# H616 register map
Vendor: Allwinner; Series: H616; File version: 0.1
CPU: other 0, little endian, MPU, no FPU, 0 interrupt priority bits
Registers are 32-bit, read-write, reset 0x0 unless marked. A register's access mark holds for its fields unless they carry their own. Offsets are from the block's base; [hi:lo] are bit positions; 'fields as' and 'values as' point back to an identical list.

## TWI0
Base 0x05002000
Same registers: TWI1 0x05002400, TWI2 0x05002800, TWI3 0x05002C00, TWI4 0x05003000, R-TWI0 0x07081400
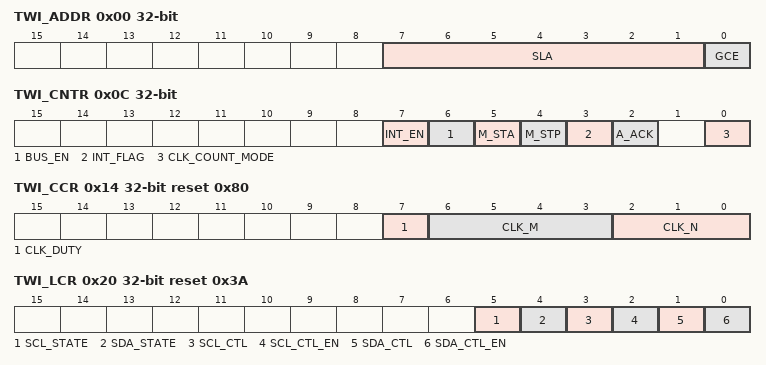
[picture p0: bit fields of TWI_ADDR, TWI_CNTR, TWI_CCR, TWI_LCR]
0x00 TWI_ADDR — TWI Slave Address
  [7:1] SLA — Slave Address 7-bit addressing: SLA6, SLA5, SLA4, SLA3, SLA2, SLA1, SLA0 10-bit addressing: 1, 1, 1, 1, 0, SLAX[9:8]
  [0] GCE — General Call Address Enable 0: Disable 1: Enable
    0=Disable; 1=Enable
0x04 TWI_XADDR — TWI Extended Slave Address
  [7:0] SLAX — Extend Slave Address SLAX[7:0]
0x08 TWI_DATA — TWI Data Byte
  [7:0] TWI_DATA — Data byte transmitted or received
0x0C TWI_CNTR — TWI Control Register
  [7] INT_EN — Interrupt Enable 0: The interrupt line always low 1: The interrupt line will go high when INT_FLAG is set.
    0=interrupt_line_always_low (The interrupt line always low); 1=interrupt_line_will_go (The interrupt line will go high when INT_FLAG is set.)
  [6] BUS_EN — TWI Bus Enable 0: The TWI bus ISDA/ISCL is ignored and the TWI Controller will not respond to any address on the bus 1: The TWI will respond to call to its slave address - and to the general call address if the GCE bit in the ADDR register is set. Note: In master operation mode, this bit should be set to `1`.
    0=TWI_bus (The TWI bus ISDA/ISCL is ignored and the TWI Controller will not respond to any address on the bus); 1=TWI_will_respond (The TWI will respond to call to its slave address - and to the general call address if the GCE bit in the ADDR register is set. Note: In master operation mode, this bit should be set to `1`.)
  [5] M_STA — Master Mode Start When M_STA is set to `1`, TWI Controller enters master mode and will transmit a START condition on the bus when the bus is free. If the M_STA bit is set to `1` when the TWI Controller is already in master mode and one or more bytes have been transmitted, then a repeated START condition will be sent. If the M_STA bit is set to `1` when the TWI is being accessed in slave mode, the TWI will complete the data transfer in slave mode then enter master mode when the bus has been released. The M_STA bit is cleared automatically after a START condition has been sent. Writing a `0` to this bit has no effect.
  [4] M_STP write-1-clears — Master Mode Stop If M_STP is set to `1` in master mode, a STOP condition is transmitted on the TWI bus. If the M_STP bit is set to `1` in slave mode, the TWI will indicate if a STOP condition has been received, but no STOP condition will be transmitted on the TWI bus. If both M_STA and M_STP bits are set, the TWI will first transmit the STOP condition (if in master mode) then transmit the START condition. The M_STP bit is cleared automatically: writing a `0` to this bit has no effect.
  [3] INT_FLAG write-1-clears — Interrupt Flag INT_FLAG is automatically set to `1` when any of 28 (out of the possible 29) states is entered (see `STAT Register` below). The only state that does not set INT_FLAG is state F8h. If the INT_EN bit is set, the interrupt line goes high when IFLG is set to `1`. If the TWI is operating in slave mode, data transfer is suspended when INT_FLAG is set and the low period of the TWI bus clock line (SCL) is stretched until `1` is written to INT_FLAG. The TWI clock line is then released and the interrupt line goes low.
  [2] A_ACK — Assert Acknowledge When A_ACK is set to `1`, an Acknowledge (low level on SDA) will be sent during the acknowledge clock pulse on the TWI bus if: (1). Either the whole of a matching 7-bit slave address or the first or the second byte of a matching 10-bit slave address has been received. (2). The general call address has been received and the GCE bit in the ADDR register is set to `1`. (3). A data byte has been received in master or slave mode. When A_ACK is `0`, a Not Acknowledge (high level on SDA) will be sent when a data byte is received in master or slave mode. If A_ACK is cleared to `0` in slave transmitter mode, the byte in the DATA register is assumed to be the `last byte`. After this byte has been transmitted, the TWI will enter state C8h then return to the idle state (status code F8h) when INT_FLAG is cleared. The TWI will not respond as a slave unless A_ACK is set.
  [0] CLK_COUNT_MODE — 0: scl clock high period count on oscl 1: scl clock high period count on iscl
    0=scl_clock_high_period_count_on_oscl; 1=scl_clock_high_period_count_on_iscl
0x10 TWI_STAT reset 0xF8 — TWI Status Register
  [7:0] STA ro — Status Information Byte Code Status 0x00: Bus error 0x08: START condition transmitted 0x10: Repeated START condition transmitted 0x18: Address + Write bit transmitted, ACK received 0x20: Address + Write bit transmitted, ACK not received 0x28: Data byte transmitted in master mode, ACK received 0x30: Data byte transmitted in master mode, ACK not received 0x38: Arbitration lost in address or data byte 0x40: Address + Read bit transmitted, ACK received 0x48: Address + Read bit transmitted, ACK not received 0x50: Data byte received in master mode, ACK transmitted 0x58: Data byte received in master mode, not ACK transmitted 0x60: Slave address + Write bit received, ACK transmitted 0x68: Arbitration lost in address as master, slave address + Write bit received, ACK transmitted 0x70: General Call address received, ACK transmitted 0x78: Arbitration lost in address as master, General Call address received, ACK transmitted 0x80: Data byte received after slave address received, ACK transmitted 0x88: Data byte received after slave address received, not ACK transmitted 0x90: Data byte received after General Call received, ACK transmitted 0x98: Data byte received after General Call received, not ACK transmitted 0xA0: STOP or repeated START condition received in slave mode 0xA8: Slave address + Read bit received, ACK transmitted 0xB0: Arbitration lost in address as master, slave address + Read bit received, ACK transmitted 0xB8: Data byte transmitted in slave mode, ACK received 0xC0: Data byte transmitted in slave mode, ACK not received 0xC8: Last byte transmitted in slave mode, ACK received 0xD0: Second Address byte + Write bit transmitted, ACK received 0xD8: Second Address byte + Write bit transmitted, ACK not received 0xF8: No relevant status information, INT_FLAG=0 Others: Reserved
0x14 TWI_CCR reset 0x80 — TWI Clock Control Register
  [7] CLK_DUTY — Setting duty cycle of Clock as Master 0: 50% 1: 40%
    0=_50_percent_; 1=_40_percent_
  [6:3] CLK_M
  [2:0] CLK_N — The TWI bus is sampled by the TWI at the frequency defined by F0: Fsamp = F0 = Fin / 2^CLK_N The TWI OSCL output frequency, in master mode, is F1 / 10: F1 = F0 / (CLK_M + 1) Foscl = F1 / 10 = Fin / (2^CLK_N * (CLK_M + 1)*10) Specially, Foscl = F1/11 when CLK_M=0 and CLK_DUTY=40% due to the delay of SCL sample debounce. For Example Fin = 24 MHz (APB clock input) For 400 kHz full speed 2Wire, CLK_N = 1, CLK_M=2 F0 = 24 MHz/2^1=12 MHz, F1= F0/(10*(2+1)) = 0.4 MHz For 100 kHz standard speed 2Wire, CLK_N=1, CLK_M=11 F0=24 MHz/2^1=12 MHz, F1=F0/(10*(11+1)) = 0.1 MHz
0x18 TWI_SRST — TWI Software Reset
  [0] SOFT_RST — Soft Reset Write `1` to this bit to reset the TWI and clear to `0` when completing Soft Reset operation.
0x1C TWI_EFR — TWI Enhance Feature Register
  [1:0] DBN — Data Byte Number Follow Read Command Control 00 : No data byte can be written after read command 01 : Only 1 byte data can be written after read command 10 : 2 bytes data can be written after read command 11 : 3 bytes data can be written after read command
0x20 TWI_LCR reset 0x3A — TWI Line Control Register
  [5] SCL_STATE ro — Current State of TWI_SCL 0 : Low 1 : High
  [4] SDA_STATE ro — Current State of TWI_SDA 0 : Low 1 : High
  [3] SCL_CTL — TWI_SCL Line State Control Bit When line control mode is enabled (bit[2] set), this bit decides the output level of TWI_SCL. 0 : Output low level 1 : Output high level
  [2] SCL_CTL_EN — TWI_SCL Line State Control Enable When this bit is set, the state of TWI_SCL is controlled by the value of bit[3]. 0 : Disable TWI_SCL line control mode 1 : Enable TWI_SCL line control mode
  [1] SDA_CTL — TWI_SDA Line State Control Bit When line control mode is enabled (bit[0] set), this bit decides the output level of TWI_SDA. 0 : Output low level 1 : Output high level
  [0] SDA_CTL_EN — TWI_SDA Line State Control Enable When this bit is set, the state of TWI_SDA is controlled by the value of bit[1]. 0 : Disable TWI_SDA line control mode 1 : Enable TWI_SDA line control mode
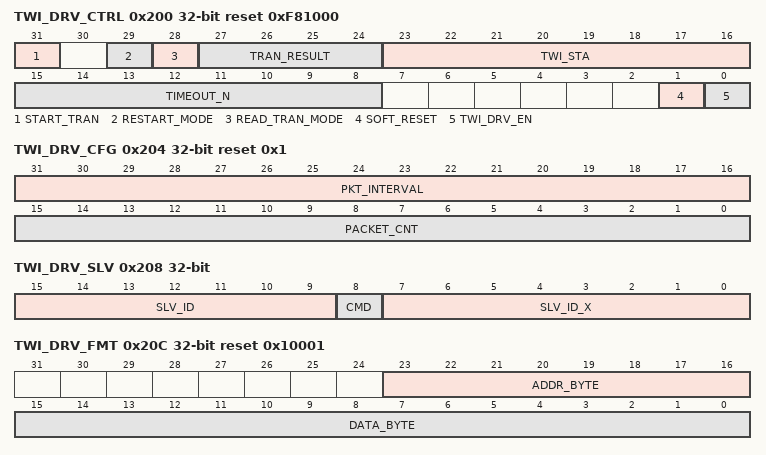
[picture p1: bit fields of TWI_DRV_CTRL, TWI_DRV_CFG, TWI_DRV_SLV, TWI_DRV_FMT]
0x200 TWI_DRV_CTRL reset 0xF81000 — TWI_DRV Control Register
  [31] START_TRAN — 0: Transmission idle 1: Start transmission Automatically cleared to `0` when finished. If slave not respond for the expected status over the time defined by TIMEOUT, current transmission will stop. All format setting and data will be loaded from registers and FIFO when transmission start.
    0=Transmission_idle; 1=Start transmission Automatically cleared to `0` when finished. If slave not respond for the expected status over the time defined by TIMEOUT, current transmission will stop. All format setting and data will be loaded from registers and FIFO when transmission start.
  [29] RESTART_MODE — 0: RESTART 1: STOP+START Define the TWI_DRV action after sending register address.
    0=RESTART; 1=STOP_plus_START (STOP+START Define the TWI_DRV action after sending register address.)
  [28] READ_TRAN_MODE — 0: send slave_id+W 1: do not send slave_id+W Setting this bit to 1 if reading from a slave which register width is equal to 0 .
    0=send slave_id+W; 1=do not send slave_id+W Setting this bit to 1 if reading from a slave which register width is equal to 0 
  [27:24] TRAN_RESULT ro — 000: OK 001: FAIL Other: Reserved
  [23:16] TWI_STA ro — 0x00: bus error 0x08: START condition transmitted 0x10: Repeated START condition transmitted 0x18: Address + Write bit transmitted, ACK received 0x20: Address + Write bit transmitted, ACK not received 0x28: Data byte transmitted in master mode, ACK received 0x30: Data byte transmitted in master mode, ACK not received 0x38: Arbitration lost in address or data byte 0x40: Address + Read bit transmitted, ACK received 0x48: Address + Read bit transmitted, ACK not received 0x50: Data byte received in master mode, ACK received 0x58: Data byte received in master mode, ACK not received 0x01: Timeout when sending 9 SCL clk Other: Reserved
  [15:8] TIMEOUT_N — When sending the 9 clock, assert fail signal when slave device does not response after N*F cycles. And software must do a reset to TWI_DRV module and send a stop condition to slave.
  [1] SOFT_RESET — 0: normal 1: reset
    0=normal; 1=reset
  [0] TWI_DRV_EN — 0: Module disable 1: Module enable (only use in TWI Master Mode)
    0=Module_disable; 1=Module enable (only use in TWI Master Mode)
0x204 TWI_DRV_CFG reset 0x1 — TWI_DRV Transmission Configuration Register
  [31:16] PKT_INTERVAL — Define the interval between each packet for PKT_INTERVAL F cycles.
  [15:0] PACKET_CNT — FIFO data be transmitted as PACKET_CNT packets in current format.
0x208 TWI_DRV_SLV — TWI_DRV Slave ID Register
  [15:9] SLV_ID — Slave device ID 7-bit addressing SLA6, SLA5, SLA4, SLA3, SLA2, SLA1, SLA0 10-bit addressing 1, 1, 1, 1, 0, SLAX[9:8]
  [8] CMD — R/W operation to slave device 0: write 1: read
    0=write; 1=read
  [7:0] SLV_ID_X — SLAX[7:0], low 8 bits for slave device ID with 10-bit addressing
0x20C TWI_DRV_FMT reset 0x10001 — TWI_DRV Packet Format Register
  [23:16] ADDR_BYTE — How many bytes be sent as slave device reg address 0~255
  [15:0] DATA_BYTE — How many bytes be sent/received as data 1~65535
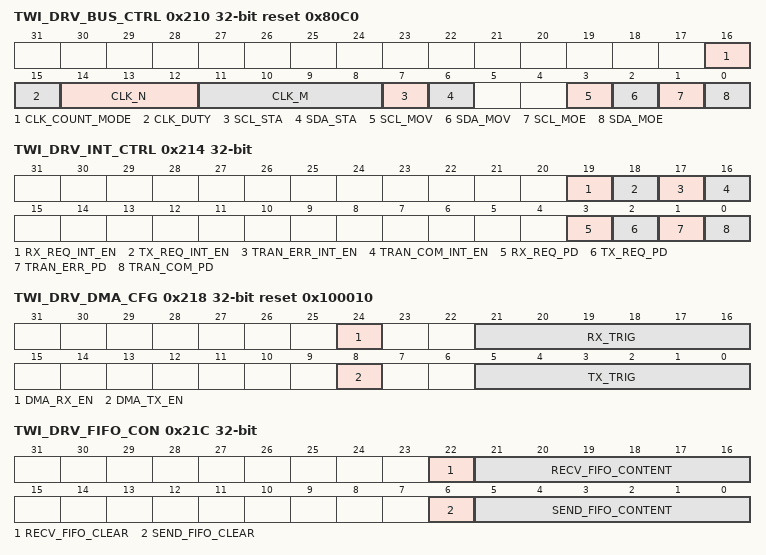
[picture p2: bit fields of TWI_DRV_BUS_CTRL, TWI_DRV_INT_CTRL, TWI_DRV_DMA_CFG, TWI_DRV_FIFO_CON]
0x210 TWI_DRV_BUS_CTRL reset 0x80C0 — TWI_DRV Bus Control Register
  [16] CLK_COUNT_MODE wo — 0: scl clock high period count on oscl 1: scl clock high period count on iscl
    values as TWI_CNTR.CLK_COUNT_MODE
  [15] CLK_DUTY — Setting duty cycle of Clock as Master 0: 50% 1: 40%
    0=_50_percent_; 1=_40_percent_
  [14:12] CLK_N — TWI_DRV bus sampling clock F0=24 MHz/2^CLK_N
  [11:8] CLK_M — TWI_DRV output SCL frequency is F =F1/10=(F0/(CLK_M+1))/10 Specially,Foscl = F1/11 when CLK_M=0 and CLK_DUTY=40% due to the delay of SCL sample debounce.
  [7] SCL_STA ro — SCL current status
  [6] SDA_STA ro — SDA current status
  [3] SCL_MOV — SCL manual output value
  [2] SDA_MOV — SDA manual output value
  [1] SCL_MOE — SCL manual output en
  [0] SDA_MOE — SDA manual output en
0x214 TWI_DRV_INT_CTRL — TWI_DRV Interrupt Control Register
  [19] RX_REQ_INT_EN
  [18] TX_REQ_INT_EN
  [17] TRAN_ERR_INT_EN
  [16] TRAN_COM_INT_EN
  [3] RX_REQ_PD write-1-clears — Set when the data byte number in RECV_FIFO reaches RX_TRIG
  [2] TX_REQ_PD write-1-clears — Set when there is no less than DMA_TX_TRIG empty byte number in SEND_FIFO
  [1] TRAN_ERR_PD write-1-clears — Packet transmission failed pending
  [0] TRAN_COM_PD write-1-clears — Packet transmission completed pending
0x218 TWI_DRV_DMA_CFG reset 0x100010 — TWI_DRV DMA Configure Register
  [24] DMA_RX_EN
  [21:16] RX_TRIG — When DMA_RX_EN set, send DMA RX Req when the data byte number in RECV_FIFO reaches RX_TRIG or Read Packet Transmission completed with RECV_FIFO not empty
  [8] DMA_TX_EN
  [5:0] TX_TRIG — When DMA_TX_EN set, send DMA TX Req when there is no less than DMA_TX_TRIG empty byte number in SEND_FIFO
0x21C TWI_DRV_FIFO_CON — TWI_DRV FIFO Content Register
  [22] RECV_FIFO_CLEAR — Set this bit to clear RECV_FIFO pointer, and this bit is cleared automatically
  [21:16] RECV_FIFO_CONTENT ro — The number of data in RECV_FIFO
  [6] SEND_FIFO_CLEAR — Set this bit to clear SEND_FIFO pointer, and this bit is cleared automatically
  [5:0] SEND_FIFO_CONTENT ro — The number of data in SEND_FIFO
0x300 TWI_DRV_SEND_FIFO_ACC — TWI_DRV Send Data FIFO Access Register
  [7:0] SEND_DATA_FIFO wo — Address of a 32x8 SEND_FIFO, which stores reg address and data sending to slave device
0x304 TWI_DRV_RECV_FIFO_ACC — TWI_DRV Receive Data FIFO Access Register
  [7:0] RECV_DATA_FIFO ro — Address of a 32x8 RECV_FIFO, which stores data received from slave device
